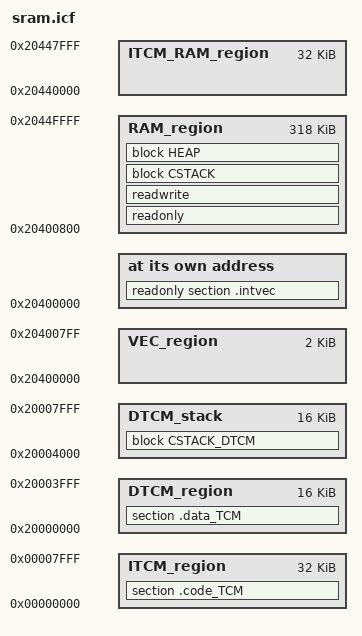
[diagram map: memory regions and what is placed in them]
/* ---------------------------------------------------------------------------- */
/*                  Atmel Microcontroller Software Support                      */
/*                       SAM Software Package License                           */
/* ---------------------------------------------------------------------------- */
/* Copyright (c) 2014, Atmel Corporation                                        */
/*                                                                              */
/* All rights reserved.                                                         */
/*                                                                              */
/* Redistribution and use in source and binary forms, with or without           */
/* modification, are permitted provided that the following condition is met:    */
/*                                                                              */
/* - Redistributions of source code must retain the above copyright notice,     */
/* this list of conditions and the disclaimer below.                            */
/*                                                                              */
/* Atmel's name may not be used to endorse or promote products derived from     */
/* this software without specific prior written permission.                     */
/*                                                                              */
/* DISCLAIMER:  THIS SOFTWARE IS PROVIDED BY ATMEL "AS IS" AND ANY EXPRESS OR   */
/* IMPLIED WARRANTIES, INCLUDING, BUT NOT LIMITED TO, THE IMPLIED WARRANTIES OF */
/* MERCHANTABILITY, FITNESS FOR A PARTICULAR PURPOSE AND NON-INFRINGEMENT ARE   */
/* DISCLAIMED. IN NO EVENT SHALL ATMEL BE LIABLE FOR ANY DIRECT, INDIRECT,      */
/* INCIDENTAL, SPECIAL, EXEMPLARY, OR CONSEQUENTIAL DAMAGES (INCLUDING, BUT NOT */
/* LIMITED TO, PROCUREMENT OF SUBSTITUTE GOODS OR SERVICES; LOSS OF USE, DATA,  */
/* OR PROFITS; OR BUSINESS INTERRUPTION) HOWEVER CAUSED AND ON ANY THEORY OF    */
/* LIABILITY, WHETHER IN CONTRACT, STRICT LIABILITY, OR TORT (INCLUDING         */
/* NEGLIGENCE OR OTHERWISE) ARISING IN ANY WAY OUT OF THE USE OF THIS SOFTWARE, */
/* EVEN IF ADVISED OF THE POSSIBILITY OF SUCH DAMAGE.                           */
/* ---------------------------------------------------------------------------- */

/*###ICF### Section handled by ICF editor, don't touch! ****/
/*-Editor annotation file-*/
/* IcfEditorFile="$TOOLKIT_DIR$\config\ide\IcfEditor\cortex_v1_0.xml" */
/*-Specials-*/
define symbol __ICFEDIT_region_ITCM_start__ = 0x0;
define symbol __ICFEDIT_region_DTCM_start__ = 0x20000000;
define symbol __ICFEDIT_intvec_start__     =  0x20400000;
/*-Memory Regions-*/
define symbol __ICFEDIT_region_RAM_start__ = 0x20400000;
define symbol __ICFEDIT_region_RAM_end__   = 0x20450000 -1;
define symbol __ICFEDIT_region_ITCMRAM_start__ = 0x20440000;
define symbol __ICFEDIT_region_ITCMRAM_end__   = 0x20448000 -1;

/*-Sizes-*/
/* ITCM and DTCM default size id 32 KB, change if it is not the case */
define symbol __ICFEDIT_size_vectors__     = 0x800;
define symbol __ICFEDIT_size_itcm__        = 0x8000;
define symbol __ICFEDIT_size_dtcm__        = 0x8000;
define symbol __ICFEDIT_size_cstack__      = 0x1000;
define symbol __ICFEDIT_size_heap__        = 0x1000;
/**** End of ICF editor section. ###ICF###*/

/*-Exports-*/
export symbol __ICFEDIT_region_RAM_start__;
export symbol __ICFEDIT_region_RAM_end__;
export symbol __ICFEDIT_size_vectors__;


define memory mem with size = 4G;
define region VEC_region     = mem:[from __ICFEDIT_region_RAM_start__ size __ICFEDIT_size_vectors__];
define region ITCM_region    = mem:[from __ICFEDIT_region_ITCM_start__ size __ICFEDIT_size_itcm__];
define region DTCM_region    = mem:[from __ICFEDIT_region_DTCM_start__ size 0x4000];
define region DTCM_stack     = mem:[from __ICFEDIT_region_DTCM_start__+0x4000 size __ICFEDIT_size_dtcm__-0x4000];
define region RAM_region     = mem:[from __ICFEDIT_region_RAM_start__+__ICFEDIT_size_vectors__ to __ICFEDIT_region_RAM_end__];
define region ITCM_RAM_region     = mem:[from __ICFEDIT_region_ITCMRAM_start__ to __ICFEDIT_region_ITCMRAM_end__];

define block CSTACK with alignment = 8, size = __ICFEDIT_size_cstack__ { };
define block HEAP   with alignment = 8, size = __ICFEDIT_size_heap__   { };
define block CSTACK_DTCM with alignment = 8, size = __ICFEDIT_size_cstack__ { };

initialize by copy { readwrite };
do not initialize                    { section .noinit };

place at address mem:__ICFEDIT_intvec_start__ { readonly section .intvec };
place in RAM_region            { readonly };
place in RAM_region            { readwrite, block CSTACK, block HEAP };

place in ITCM_region           {section .code_TCM };
place in DTCM_region           {section .data_TCM };
place in DTCM_stack            {block CSTACK_DTCM};
initialize by copy             {readonly section .code_TCM };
